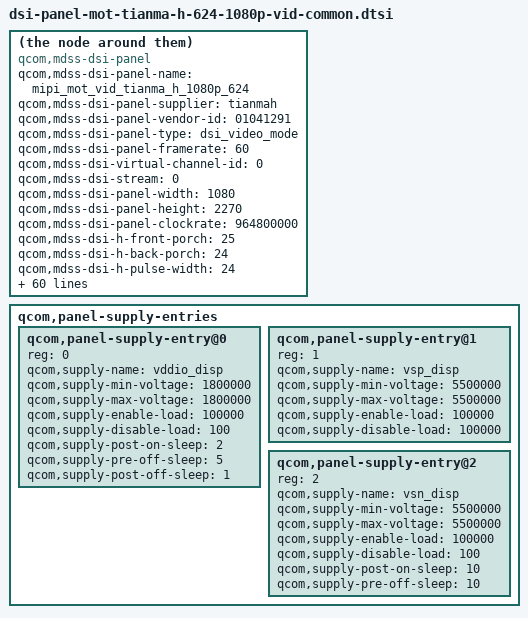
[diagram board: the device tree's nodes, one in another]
/* Copyright (c) 2016, The Linux Foundation. All rights reserved.
 *
 * This program is free software; you can redistribute it and/or modify
 * it under the terms of the GNU General Public License version 2 and
 * only version 2 as published by the Free Software Foundation.
 *
 * This program is distributed in the hope that it will be useful,
 * but WITHOUT ANY WARRANTY; without even the implied warranty of
 * MERCHANTABILITY or FITNESS FOR A PARTICULAR PURPOSE.  See the
 * GNU General Public License for more details.
 */

compatible = "qcom,mdss-dsi-panel";
qcom,mdss-dsi-panel-name = "mipi_mot_vid_tianma_h_1080p_624";
qcom,mdss-dsi-panel-supplier = "tianmah";
qcom,mdss-dsi-panel-vendor-id = "01041291";
qcom,mdss-dsi-panel-type = "dsi_video_mode";
qcom,mdss-dsi-panel-framerate = <60>;
qcom,mdss-dsi-virtual-channel-id = <0>;
qcom,mdss-dsi-stream = <0>;
qcom,mdss-dsi-panel-width = <1080>;
qcom,mdss-dsi-panel-height = <2270>;
qcom,mdss-dsi-panel-clockrate = <964800000>;
qcom,mdss-dsi-h-front-porch = <25>;
qcom,mdss-dsi-h-back-porch = <24>;
qcom,mdss-dsi-h-pulse-width = <24>;
qcom,mdss-dsi-h-sync-skew = <0>;
qcom,mdss-dsi-v-front-porch = <42>;
qcom,mdss-dsi-v-back-porch = <7>;
qcom,mdss-dsi-v-pulse-width = <5>;
qcom,mdss-dsi-h-left-border = <0>;
qcom,mdss-dsi-h-right-border = <0>;
qcom,mdss-dsi-v-top-border = <0>;
qcom,mdss-dsi-v-bottom-border = <0>;
qcom,mdss-dsi-bpp = <24>;
qcom,mdss-dsi-underflow-color = <0xff>;
qcom,mdss-dsi-border-color = <0>;
qcom,mdss-dsi-on-command = [
	39 01 00 00 00 00 04 B9 83 11 2a
	39 01 00 00 00 00 05 CF 00 14 00 C0
	05 01 00 00 5a 00 02 11 00
	05 01 00 00 14 00 02 29 00
	39 01 00 00 00 00 03 51 00 00
	15 01 00 00 00 00 02 53 2C
	15 01 00 00 05 00 02 55 01
        39 01 00 00 00 00 17 E4 2D 01 2C 00 08 00 10 08 04
                04 8D 8D 8D 99 99 C2 C2 FF FF FF FF EF
        39 01 00 00 00 00 05 c9 04 08 B9 01
	15 01 00 00 00 00 02 cc 08
        39 01 00 00 00 00 03 ba 73 23];/* display on */
qcom,mdss-dsi-off-command = [
	05 01 00 00 23 00 01 28		/* display_off */
	05 01 00 00 78 00 01 10];	/* enter sleep mode */


qcom,mdss-dsi-on-command-state = "dsi_lp_mode";
qcom,mdss-dsi-off-command-state = "dsi_lp_mode";

qcom,mdss-dsi-cabc-ui-command = [
        39 01 00 00 05 00 04 b9 83 11 2a
	15 01 00 00 05 00 02 55 01
        39 01 00 00 00 00 17 E4 2D 01 2C 00 08 00 10 08 04
                04 8D 8D 8D 99 99 C2 C2 FF FF FF FF EF];

qcom,mdss-dsi-cabc-ui-command-state = "dsi_hs_mode";
qcom,mdss-dsi-cabc-mv-command = [
        39 01 00 00 05 00 04 b9 83 11 2a
	15 01 00 00 05 00 02 55 03
        39 01 00 00 00 00 17 E4 2D 01 2C 00 08 00 10 08 04
                04 00 22 49 FF 07 41 A9 E0 F1 AA FF EF];

qcom,mdss-dsi-cabc-mv-command-state = "dsi_hs_mode";
qcom,mdss-dsi-cabc-dis-command = [15 01 00 00 00 00 02 55 00];
qcom,mdss-dsi-cabc-dis-command-state = "dsi_hs_mode";

qcom,mdss-dsi-h-sync-pulse = <0>;
qcom,mdss-dsi-traffic-mode = "burst_mode";
qcom,mdss-dsi-bllp-eof-power-mode;
qcom,mdss-dsi-bllp-power-mode;
qcom,mdss-dsi-lane-0-state;
qcom,mdss-dsi-lane-1-state;
qcom,mdss-dsi-lane-2-state;
qcom,mdss-dsi-lane-3-state;
qcom,mdss-dsi-panel-timings-phy-v2 = [25 20 08 0a 06 03 04 a0
	25 20 08 0a 06 03 04 a0
	25 20 08 0a 06 03 04 a0
	25 20 08 0a 06 03 04 a0
	25 1d 08 0a 06 03 04 a0];
qcom,mdss-dsi-t-clk-post = <0x0e>;
qcom,mdss-dsi-t-clk-pre = <0x33>;
qcom,bklt-dcs-2bytes-enabled;
qcom,mdss-dsi-bl-min-level = <1>;
qcom,mdss-dsi-bl-max-level = <4095>;
qcom,mdss-dsi-dma-trigger = "trigger_sw";
qcom,mdss-dsi-mdp-trigger = "none";
qcom,mdss-dsi-bl-pmic-control-type = "bl_ctrl_dcs";
qcom,mdss-dsi-reset-sequence = <1 2>, <0 2>, <1 50>;
qcom,mdss-dsi-lp11-init;
//qcom,mdss-dsi-tx-eot-append;
//qcom,mdss-dsi-init-delay-us = <50000>;
qcom,mdss-dsi-no-panel-on-read-support;
qcom,mdss-panel-reg-read-lp-enable;

//qcom,esd-check-enabled;
qcom,mdss-dsi-panel-status-check-mode = "reg_read";
qcom,mdss-dsi-panel-status-read-length = <1>;
qcom,mdss-dsi-panel-status-command = [06 01 00 01 00 00 01 0A];
qcom,mdss-dsi-panel-status-command-state = "dsi_hs_mode";
qcom,mdss-dsi-panel-status-value = <0x9D>;

qcom,panel-supply-entries {
	#address-cells = <1>;
	#size-cells = <0>;

	qcom,panel-supply-entry@0 {
		reg = <0>;
		qcom,supply-name = "vddio_disp";
		qcom,supply-min-voltage = <1800000>;
		qcom,supply-max-voltage = <1800000>;
		qcom,supply-enable-load = <100000>;
		qcom,supply-disable-load = <100>;
		qcom,supply-post-on-sleep = <2>;
		qcom,supply-pre-off-sleep = <5>;
		qcom,supply-post-off-sleep = <1>;
	};

	qcom,panel-supply-entry@1 {
		reg = <1>;
		qcom,supply-name = "vsp_disp";
		qcom,supply-min-voltage = <5500000>;
		qcom,supply-max-voltage = <5500000>;
		qcom,supply-enable-load = <100000>;
		qcom,supply-disable-load = <100000>;
	};

	qcom,panel-supply-entry@2 {
		reg = <2>;
		qcom,supply-name = "vsn_disp";
		qcom,supply-min-voltage = <5500000>;
		qcom,supply-max-voltage = <5500000>;
		qcom,supply-enable-load = <100000>;
		qcom,supply-disable-load = <100>;
		qcom,supply-post-on-sleep = <10>;
		qcom,supply-pre-off-sleep = <10>;
	};
};
